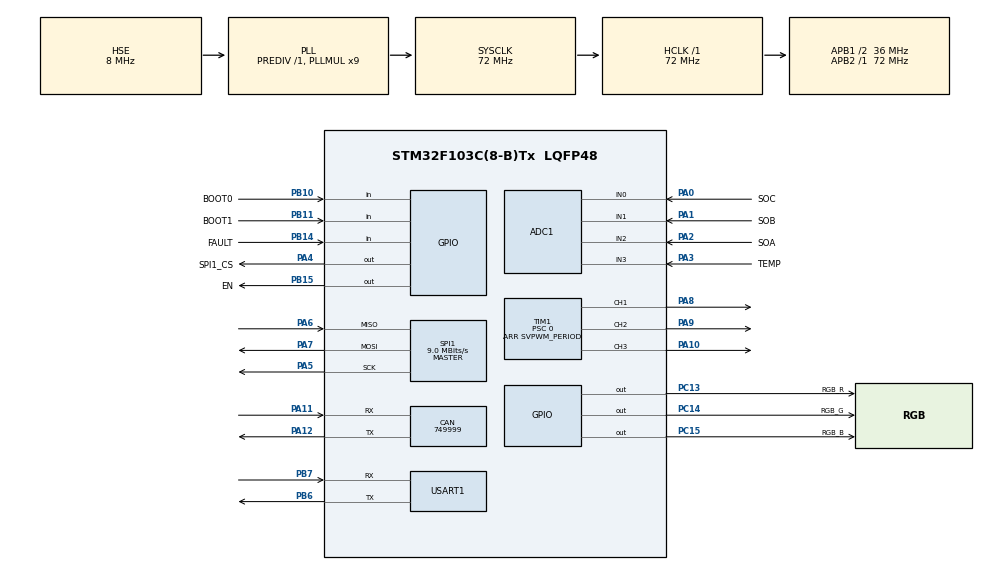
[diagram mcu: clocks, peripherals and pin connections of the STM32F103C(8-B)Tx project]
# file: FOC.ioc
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ADC1.Channel-0\#ChannelRegularConversion=ADC_CHANNEL_0
ADC1.Channel-1\#ChannelRegularConversion=ADC_CHANNEL_1
ADC1.Channel-2\#ChannelRegularConversion=ADC_CHANNEL_2
ADC1.Channel-3\#ChannelRegularConversion=ADC_CHANNEL_3
ADC1.ContinuousConvMode=ENABLE
ADC1.EnableInjectedConversion=DISABLE
ADC1.ExternalTrigConv=ADC_EXTERNALTRIGCONV_T4_CC4
ADC1.NbrOfConversion=4
ADC1.NbrOfConversionFlag=1
ADC1.Rank-0\#ChannelRegularConversion=1
ADC1.Rank-1\#ChannelRegularConversion=2
ADC1.Rank-2\#ChannelRegularConversion=3
ADC1.Rank-3\#ChannelRegularConversion=4
ADC1.SamplingTime-0\#ChannelRegularConversion=ADC_SAMPLETIME_1CYCLE_5
ADC1.SamplingTime-1\#ChannelRegularConversion=ADC_SAMPLETIME_1CYCLE_5
ADC1.SamplingTime-2\#ChannelRegularConversion=ADC_SAMPLETIME_1CYCLE_5
ADC1.SamplingTime-3\#ChannelRegularConversion=ADC_SAMPLETIME_1CYCLE_5
ADC1.master=1
CAN.CalculateBaudRate=749999
CAN.CalculateTimeBit=1333
CAN.CalculateTimeQuantum=444.44444444444446
Dma.ADC1.2.Direction=DMA_PERIPH_TO_MEMORY
Dma.ADC1.2.Instance=DMA1_Channel1
Dma.ADC1.2.MemDataAlignment=DMA_MDATAALIGN_HALFWORD
Dma.ADC1.2.MemInc=DMA_MINC_ENABLE
Dma.ADC1.2.Mode=DMA_CIRCULAR
Dma.ADC1.2.PeriphDataAlignment=DMA_PDATAALIGN_HALFWORD
Dma.ADC1.2.PeriphInc=DMA_PINC_DISABLE
Dma.ADC1.2.Priority=DMA_PRIORITY_LOW
Dma.Request0=USART1_RX
Dma.Request1=USART1_TX
Dma.Request2=ADC1
Dma.USART1_RX.0.Direction=DMA_PERIPH_TO_MEMORY
Dma.USART1_RX.0.Instance=DMA1_Channel5
Dma.USART1_RX.0.MemDataAlignment=DMA_MDATAALIGN_BYTE
Dma.USART1_RX.0.MemInc=DMA_MINC_ENABLE
Dma.USART1_RX.0.Mode=DMA_NORMAL
Dma.USART1_RX.0.PeriphDataAlignment=DMA_PDATAALIGN_BYTE
Dma.USART1_RX.0.PeriphInc=DMA_PINC_DISABLE
Dma.USART1_RX.0.Priority=DMA_PRIORITY_LOW
Dma.USART1_TX.1.Direction=DMA_MEMORY_TO_PERIPH
Dma.USART1_TX.1.Instance=DMA1_Channel4
Dma.USART1_TX.1.MemDataAlignment=DMA_MDATAALIGN_BYTE
Dma.USART1_TX.1.MemInc=DMA_MINC_ENABLE
Dma.USART1_TX.1.Mode=DMA_NORMAL
Dma.USART1_TX.1.PeriphDataAlignment=DMA_PDATAALIGN_BYTE
Dma.USART1_TX.1.PeriphInc=DMA_PINC_DISABLE
Dma.USART1_TX.1.Priority=DMA_PRIORITY_LOW
Mcu.Family=STM32F1
Mcu.Name=STM32F103C(8-B)Tx
Mcu.Package=LQFP48
Mcu.UserConstants=SVPWM_PERIOD,3200
NVIC.DMA1_Channel1_IRQn=true\:0\:0\:false\:false\:true\:false\:true\:true
NVIC.DMA1_Channel4_IRQn=true\:0\:0\:false\:false\:true\:false\:true\:true
NVIC.DMA1_Channel5_IRQn=true\:0\:0\:false\:false\:true\:false\:true\:true
NVIC.PriorityGroup=NVIC_PRIORITYGROUP_4
PA0-WKUP.GPIO_Label=SOC
PA0-WKUP.Signal=ADCx_IN0
PA1.GPIO_Label=SOB
PA1.Signal=ADCx_IN1
PA10.GPIO_ModeDefaultPP=GPIO_MODE_AF_PP
PA10.GPIO_Speed=GPIO_SPEED_FREQ_LOW
PA10.Signal=S_TIM1_CH3
PA11.Mode=CAN_Activate
PA11.Signal=CAN_RX
PA12.Mode=CAN_Activate
PA12.Signal=CAN_TX
PA13.Mode=Serial_Wire
PA13.Signal=SYS_JTMS-SWDIO
PA14.Mode=Serial_Wire
PA14.Signal=SYS_JTCK-SWCLK
PA2.GPIO_Label=SOA
PA2.Signal=ADCx_IN2
PA3.GPIO_Label=TEMP
PA3.Signal=ADCx_IN3
PA4.GPIO_Label=SPI1_CS
PA4.Signal=GPIO_Output
PA5.Mode=Full_Duplex_Master
PA5.Signal=SPI1_SCK
PA6.Mode=Full_Duplex_Master
PA6.Signal=SPI1_MISO
PA7.Mode=Full_Duplex_Master
PA7.Signal=SPI1_MOSI
PA8.GPIO_ModeDefaultPP=GPIO_MODE_AF_PP
PA8.GPIO_Speed=GPIO_SPEED_FREQ_LOW
PA8.Signal=S_TIM1_CH1
PA9.GPIO_ModeDefaultPP=GPIO_MODE_AF_PP
PA9.GPIO_Speed=GPIO_SPEED_FREQ_LOW
PA9.Signal=S_TIM1_CH2
PB10.GPIO_Label=BOOT0
PB10.GPIO_PuPd=GPIO_PULLUP
PB10.Signal=GPIO_Input
PB11.GPIO_Label=BOOT1
PB11.GPIO_PuPd=GPIO_PULLDOWN
PB11.Signal=GPIO_Input
PB14.GPIO_Label=FAULT
PB14.GPIO_PuPd=GPIO_NOPULL
PB14.Signal=GPIO_Input
PB15.GPIO_Label=EN
PB15.GPIO_PuPd=GPIO_PULLDOWN
PB15.Signal=GPIO_Output
PB6.Mode=Asynchronous
PB6.Signal=USART1_TX
PB7.Mode=Asynchronous
PB7.Signal=USART1_RX
PC13-TAMPER-RTC.GPIO_Label=RGB_R
PC13-TAMPER-RTC.GPIO_PuPd=GPIO_PULLUP
PC13-TAMPER-RTC.PinState=GPIO_PIN_SET
PC13-TAMPER-RTC.Signal=GPIO_Output
PC14-OSC32_IN.GPIO_Label=RGB_G
PC14-OSC32_IN.GPIO_PuPd=GPIO_PULLUP
PC14-OSC32_IN.PinState=GPIO_PIN_SET
PC14-OSC32_IN.Signal=GPIO_Output
PC15-OSC32_OUT.GPIO_Label=RGB_B
PC15-OSC32_OUT.GPIO_PuPd=GPIO_PULLUP
PC15-OSC32_OUT.PinState=GPIO_PIN_SET
PC15-OSC32_OUT.Signal=GPIO_Output
PD0-OSC_IN.Mode=HSE-External-Oscillator
PD0-OSC_IN.Signal=RCC_OSC_IN
PD1-OSC_OUT.Mode=HSE-External-Oscillator
PD1-OSC_OUT.Signal=RCC_OSC_OUT
ProjectManager.HeapSize=0x200
ProjectManager.StackSize=0x400
ProjectManager.TargetToolchain=STM32CubeIDE
RCC.ADCPresc=RCC_ADCPCLK2_DIV6
RCC.AHBFreq_Value=72000000
RCC.APB1CLKDivider=RCC_HCLK_DIV2
RCC.APB1Freq_Value=36000000
RCC.APB1TimFreq_Value=72000000
RCC.APB2Freq_Value=72000000
RCC.APB2TimFreq_Value=72000000
RCC.HCLKFreq_Value=72000000
RCC.PLLMUL=RCC_PLL_MUL9
RCC.PLLSourceVirtual=RCC_PLLSOURCE_HSE
RCC.SYSCLKFreq_VALUE=72000000
RCC.SYSCLKSource=RCC_SYSCLKSOURCE_PLLCLK
RCC.USBFreq_Value=48000000
RCC.USBPrescaler=RCC_USBCLKSOURCE_PLL_DIV1_5
SH.ADCx_IN0.0=ADC1_IN0,IN0
SH.ADCx_IN1.0=ADC1_IN1,IN1
SH.ADCx_IN2.0=ADC1_IN2,IN2
SH.ADCx_IN3.0=ADC1_IN3,IN3
SH.S_TIM1_CH1.0=TIM1_CH1,PWM Generation1 CH1
SH.S_TIM1_CH2.0=TIM1_CH2,PWM Generation2 CH2
SH.S_TIM1_CH3.0=TIM1_CH3,PWM Generation3 CH3
SPI1.BaudRatePrescaler=SPI_BAUDRATEPRESCALER_8
SPI1.CLKPhase=SPI_PHASE_2EDGE
SPI1.CalculateBaudRate=9.0 MBits/s
SPI1.DataSize=SPI_DATASIZE_16BIT
SPI1.Direction=SPI_DIRECTION_2LINES
SPI1.Mode=SPI_MODE_MASTER
SPI1.VirtualType=VM_MASTER
TIM1.BreakPolarity=TIM_BREAKPOLARITY_HIGH
TIM1.Channel-PWM\ Generation1\ CH1=TIM_CHANNEL_1
TIM1.Channel-PWM\ Generation2\ CH2=TIM_CHANNEL_2
TIM1.Channel-PWM\ Generation3\ CH3=TIM_CHANNEL_3
TIM1.ClockDivision=TIM_CLOCKDIVISION_DIV1
TIM1.CounterMode=TIM_COUNTERMODE_CENTERALIGNED1
TIM1.OCIdleState_1=TIM_OCIDLESTATE_RESET
TIM1.OCIdleState_2=TIM_OCIDLESTATE_RESET
TIM1.OCMode_PWM-PWM\ Generation1\ CH1=TIM_OCMODE_PWM1
TIM1.OCMode_PWM-PWM\ Generation2\ CH2=TIM_OCMODE_PWM1
TIM1.OCMode_PWM-PWM\ Generation3\ CH3=TIM_OCMODE_PWM1
TIM1.Period=SVPWM_PERIOD
TIM1.Prescaler=0
TIM1.Pulse-PWM\ Generation1\ CH1=SVPWM_PERIOD/4
TIM1.Pulse-PWM\ Generation2\ CH2=SVPWM_PERIOD/4
TIM1.Pulse-PWM\ Generation3\ CH3=SVPWM_PERIOD/4
TIM1.TIM_MasterOutputTrigger=TIM_TRGO_ENABLE
TIM1.TIM_MasterSlaveMode=TIM_MASTERSLAVEMODE_ENABLE
TIM4.Channel-PWM\ Generation4\ No\ Output=TIM_CHANNEL_4
TIM4.CounterMode=TIM_COUNTERMODE_CENTERALIGNED1
TIM4.Period=SVPWM_PERIOD
TIM4.Pulse-PWM\ Generation4\ No\ Output=SVPWM_PERIOD-2
TIM4.TIM_MasterOutputTrigger=TIM_TRGO_UPDATE
TIM4.TIM_MasterSlaveMode=TIM_MASTERSLAVEMODE_ENABLE
USART1.VirtualMode=VM_ASYNC
VP_TIM1_VS_ClockSourceINT.Mode=Internal
VP_TIM4_VS_ClockSourceINT.Mode=Internal
VP_TIM4_VS_ClockSourceITR.Mode=TriggerSource_ITR0
VP_TIM4_VS_ControllerModeTrigger.Mode=Trigger Mode
VP_TIM4_VS_no_output4.Mode=PWM Generation4 No Output
board=custom

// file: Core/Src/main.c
/* USER CODE BEGIN Header */
/**
  ******************************************************************************
  * @file           : main.c
  * @brief          : Main program body
  ******************************************************************************
  * @attention
  *
  * Copyright (c) 2024 STMicroelectronics.
  * All rights reserved.
  *
  * This software is licensed under terms that can be found in the LICENSE file
  * in the root directory of this software component.
  * If no LICENSE file comes with this software, it is provided AS-IS.
  *
  ******************************************************************************
  */
/* USER CODE END Header */
#include "main.h"
#include "adc.h"
#include "can.h"
#include "dma.h"
#include "spi.h"
#include "tim.h"
#include "usart.h"
#include "gpio.h"

/* USER CODE BEGIN Includes */
#include "utilities.h"
#include "MainThread.h"

/* USER CODE END Includes */

void SystemClock_Config(void);

int main(void)
{

  /* MCU Configuration--------------------------------------------------------*/

  /* Reset of all peripherals, Initializes the Flash interface and the Systick. */
  HAL_Init();

  /* Configure the system clock */
  SystemClock_Config();

  /* Initialize all configured peripherals */
  MX_GPIO_Init();
  MX_DMA_Init();
  MX_ADC1_Init();
  MX_CAN_Init();
  MX_SPI1_Init();
  MX_TIM1_Init();
  MX_USART1_UART_Init();
  MX_TIM4_Init();
  /* USER CODE BEGIN 2 */
  Main_Thread();
  /* USER CODE END 2 */

  /* Infinite loop */
  while (1)
  {

  }
}

void SystemClock_Config(void)
{
  RCC_OscInitTypeDef RCC_OscInitStruct = {0};
  RCC_ClkInitTypeDef RCC_ClkInitStruct = {0};
  RCC_PeriphCLKInitTypeDef PeriphClkInit = {0};

  /** Initializes the RCC Oscillators according to the specified parameters
  * in the RCC_OscInitTypeDef structure.
  */
  RCC_OscInitStruct.OscillatorType = RCC_OSCILLATORTYPE_HSE;
  RCC_OscInitStruct.HSEState = RCC_HSE_ON;
  RCC_OscInitStruct.HSEPredivValue = RCC_HSE_PREDIV_DIV1;
  RCC_OscInitStruct.HSIState = RCC_HSI_ON;
  RCC_OscInitStruct.PLL.PLLState = RCC_PLL_ON;
  RCC_OscInitStruct.PLL.PLLSource = RCC_PLLSOURCE_HSE;
  RCC_OscInitStruct.PLL.PLLMUL = RCC_PLL_MUL9;
  if (HAL_RCC_OscConfig(&RCC_OscInitStruct) != HAL_OK)
  {
    Error_Handler();
  }

  /** Initializes the CPU, AHB and APB buses clocks
  */
  RCC_ClkInitStruct.ClockType = RCC_CLOCKTYPE_HCLK|RCC_CLOCKTYPE_SYSCLK
                              |RCC_CLOCKTYPE_PCLK1|RCC_CLOCKTYPE_PCLK2;
  RCC_ClkInitStruct.SYSCLKSource = RCC_SYSCLKSOURCE_PLLCLK;
  RCC_ClkInitStruct.AHBCLKDivider = RCC_SYSCLK_DIV1;
  RCC_ClkInitStruct.APB1CLKDivider = RCC_HCLK_DIV2;
  RCC_ClkInitStruct.APB2CLKDivider = RCC_HCLK_DIV1;

  if (HAL_RCC_ClockConfig(&RCC_ClkInitStruct, FLASH_LATENCY_2) != HAL_OK)
  {
    Error_Handler();
  }
  PeriphClkInit.PeriphClockSelection = RCC_PERIPHCLK_ADC;
  PeriphClkInit.AdcClockSelection = RCC_ADCPCLK2_DIV6;
  if (HAL_RCCEx_PeriphCLKConfig(&PeriphClkInit) != HAL_OK)
  {
    Error_Handler();
  }
}

void Error_Handler(void)
{
  __disable_irq();
  while (1)
  {
  }
}
